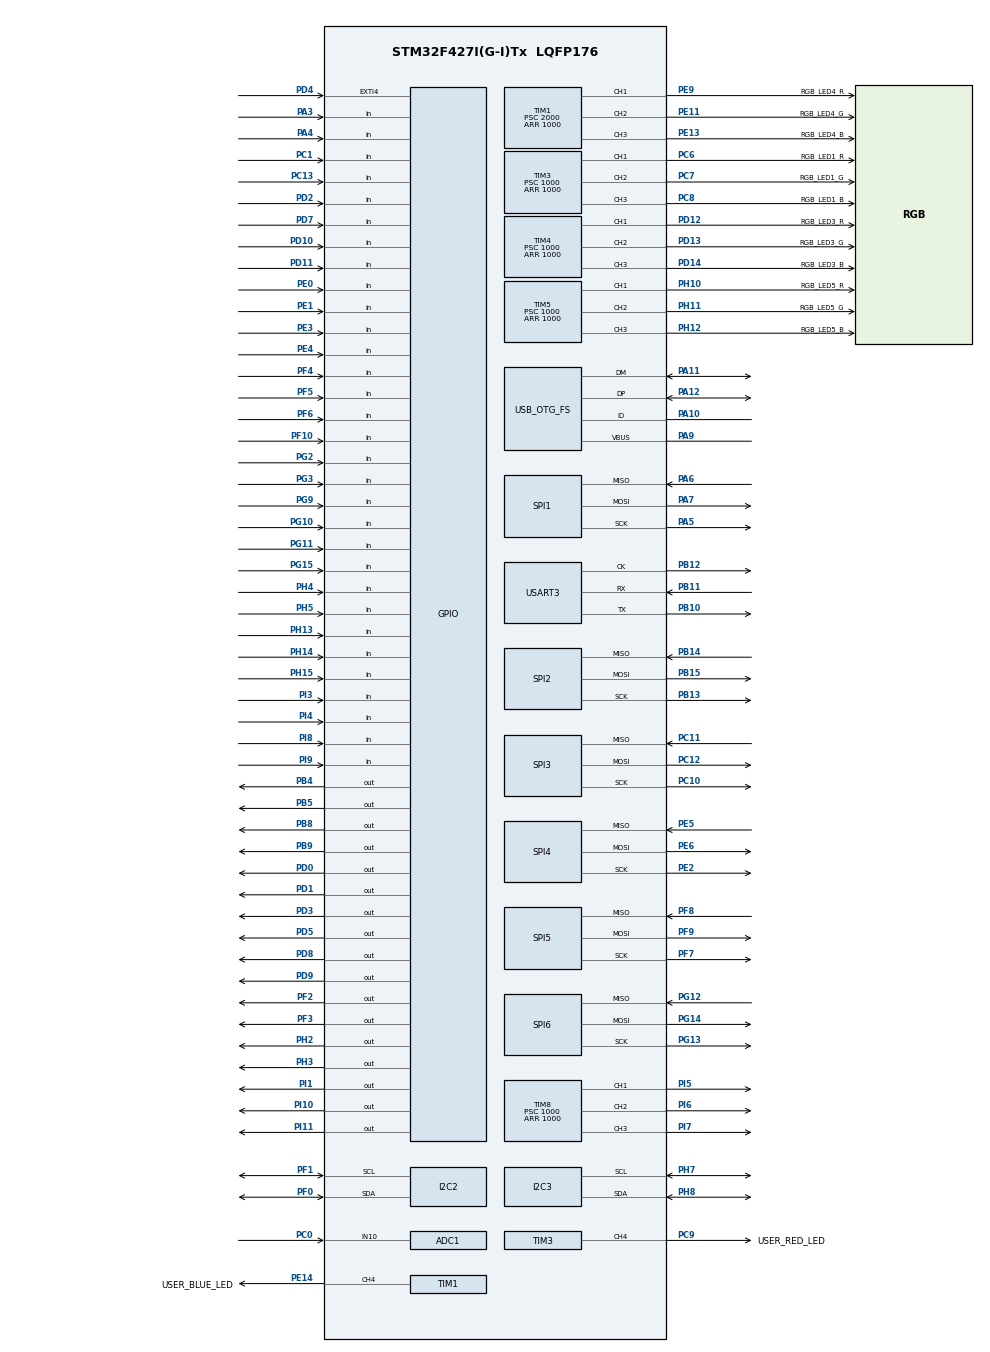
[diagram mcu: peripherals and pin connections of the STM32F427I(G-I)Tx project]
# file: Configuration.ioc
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ADC1.Channel-0\#ChannelRegularConversion=ADC_CHANNEL_10
ADC1.NbrOfConversionFlag=1
ADC1.master=1
Dma.Request0=SPI3_RX
Dma.Request1=SPI3_TX
Dma.Request10=USART3_RX
Dma.Request11=USART3_TX
Dma.Request2=SPI4_RX
Dma.Request3=SPI4_TX
Dma.Request4=SPI5_TX
Dma.Request5=SPI5_RX
Dma.Request6=SPI6_RX
Dma.Request7=SPI6_TX
Dma.Request8=SPI1_RX
Dma.Request9=SPI2_RX
Dma.SPI1_RX.8.Channel=DMA_CHANNEL_3
Dma.SPI1_RX.8.Direction=DMA_PERIPH_TO_MEMORY
Dma.SPI1_RX.8.FIFOMode=DMA_FIFOMODE_DISABLE
Dma.SPI1_RX.8.Instance=DMA2_Stream2
Dma.SPI1_RX.8.MemDataAlignment=DMA_MDATAALIGN_BYTE
Dma.SPI1_RX.8.MemInc=DMA_MINC_ENABLE
Dma.SPI1_RX.8.Mode=DMA_NORMAL
Dma.SPI1_RX.8.PeriphDataAlignment=DMA_PDATAALIGN_BYTE
Dma.SPI1_RX.8.PeriphInc=DMA_PINC_DISABLE
Dma.SPI1_RX.8.Priority=DMA_PRIORITY_HIGH
Dma.SPI2_RX.9.Channel=DMA_CHANNEL_0
Dma.SPI2_RX.9.Direction=DMA_PERIPH_TO_MEMORY
Dma.SPI2_RX.9.FIFOMode=DMA_FIFOMODE_DISABLE
Dma.SPI2_RX.9.Instance=DMA1_Stream3
Dma.SPI2_RX.9.MemDataAlignment=DMA_MDATAALIGN_BYTE
Dma.SPI2_RX.9.MemInc=DMA_MINC_ENABLE
Dma.SPI2_RX.9.Mode=DMA_NORMAL
Dma.SPI2_RX.9.PeriphDataAlignment=DMA_PDATAALIGN_BYTE
Dma.SPI2_RX.9.PeriphInc=DMA_PINC_DISABLE
Dma.SPI2_RX.9.Priority=DMA_PRIORITY_MEDIUM
Dma.SPI3_RX.0.Channel=DMA_CHANNEL_0
Dma.SPI3_RX.0.Direction=DMA_PERIPH_TO_MEMORY
Dma.SPI3_RX.0.FIFOMode=DMA_FIFOMODE_DISABLE
Dma.SPI3_RX.0.Instance=DMA1_Stream0
Dma.SPI3_RX.0.MemDataAlignment=DMA_MDATAALIGN_BYTE
Dma.SPI3_RX.0.MemInc=DMA_MINC_ENABLE
Dma.SPI3_RX.0.Mode=DMA_NORMAL
Dma.SPI3_RX.0.PeriphDataAlignment=DMA_PDATAALIGN_BYTE
Dma.SPI3_RX.0.PeriphInc=DMA_PINC_DISABLE
Dma.SPI3_RX.0.Priority=DMA_PRIORITY_MEDIUM
Dma.SPI3_TX.1.Channel=DMA_CHANNEL_0
Dma.SPI3_TX.1.Direction=DMA_MEMORY_TO_PERIPH
Dma.SPI3_TX.1.FIFOMode=DMA_FIFOMODE_DISABLE
Dma.SPI3_TX.1.Instance=DMA1_Stream7
Dma.SPI3_TX.1.MemDataAlignment=DMA_MDATAALIGN_BYTE
Dma.SPI3_TX.1.MemInc=DMA_MINC_ENABLE
Dma.SPI3_TX.1.Mode=DMA_NORMAL
Dma.SPI3_TX.1.PeriphDataAlignment=DMA_PDATAALIGN_BYTE
Dma.SPI3_TX.1.PeriphInc=DMA_PINC_DISABLE
Dma.SPI3_TX.1.Priority=DMA_PRIORITY_HIGH
Dma.SPI4_RX.2.Channel=DMA_CHANNEL_4
Dma.SPI4_RX.2.Direction=DMA_PERIPH_TO_MEMORY
Dma.SPI4_RX.2.FIFOMode=DMA_FIFOMODE_DISABLE
Dma.SPI4_RX.2.Instance=DMA2_Stream0
Dma.SPI4_RX.2.MemDataAlignment=DMA_MDATAALIGN_BYTE
Dma.SPI4_RX.2.MemInc=DMA_MINC_ENABLE
Dma.SPI4_RX.2.Mode=DMA_NORMAL
Dma.SPI4_RX.2.PeriphDataAlignment=DMA_PDATAALIGN_BYTE
Dma.SPI4_RX.2.PeriphInc=DMA_PINC_DISABLE
Dma.SPI4_RX.2.Priority=DMA_PRIORITY_MEDIUM
Dma.SPI4_TX.3.Channel=DMA_CHANNEL_4
Dma.SPI4_TX.3.Direction=DMA_MEMORY_TO_PERIPH
Dma.SPI4_TX.3.FIFOMode=DMA_FIFOMODE_DISABLE
Dma.SPI4_TX.3.Instance=DMA2_Stream1
Dma.SPI4_TX.3.MemDataAlignment=DMA_MDATAALIGN_BYTE
Dma.SPI4_TX.3.MemInc=DMA_MINC_ENABLE
Dma.SPI4_TX.3.Mode=DMA_NORMAL
Dma.SPI4_TX.3.PeriphDataAlignment=DMA_PDATAALIGN_BYTE
Dma.SPI4_TX.3.PeriphInc=DMA_PINC_DISABLE
Dma.SPI4_TX.3.Priority=DMA_PRIORITY_HIGH
Dma.SPI5_RX.5.Channel=DMA_CHANNEL_2
Dma.SPI5_RX.5.Direction=DMA_PERIPH_TO_MEMORY
Dma.SPI5_RX.5.FIFOMode=DMA_FIFOMODE_DISABLE
Dma.SPI5_RX.5.Instance=DMA2_Stream3
Dma.SPI5_RX.5.MemDataAlignment=DMA_MDATAALIGN_BYTE
Dma.SPI5_RX.5.MemInc=DMA_MINC_ENABLE
Dma.SPI5_RX.5.Mode=DMA_NORMAL
Dma.SPI5_RX.5.PeriphDataAlignment=DMA_PDATAALIGN_BYTE
Dma.SPI5_RX.5.PeriphInc=DMA_PINC_DISABLE
Dma.SPI5_RX.5.Priority=DMA_PRIORITY_HIGH
Dma.SPI5_TX.4.Channel=DMA_CHANNEL_2
Dma.SPI5_TX.4.Direction=DMA_MEMORY_TO_PERIPH
Dma.SPI5_TX.4.FIFOMode=DMA_FIFOMODE_DISABLE
Dma.SPI5_TX.4.Instance=DMA2_Stream4
Dma.SPI5_TX.4.MemDataAlignment=DMA_MDATAALIGN_BYTE
Dma.SPI5_TX.4.MemInc=DMA_MINC_ENABLE
Dma.SPI5_TX.4.Mode=DMA_NORMAL
Dma.SPI5_TX.4.PeriphDataAlignment=DMA_PDATAALIGN_BYTE
Dma.SPI5_TX.4.PeriphInc=DMA_PINC_DISABLE
Dma.SPI5_TX.4.Priority=DMA_PRIORITY_MEDIUM
Dma.SPI6_RX.6.Channel=DMA_CHANNEL_1
Dma.SPI6_RX.6.Direction=DMA_PERIPH_TO_MEMORY
Dma.SPI6_RX.6.FIFOMode=DMA_FIFOMODE_DISABLE
Dma.SPI6_RX.6.Instance=DMA2_Stream6
Dma.SPI6_RX.6.MemDataAlignment=DMA_MDATAALIGN_BYTE
Dma.SPI6_RX.6.MemInc=DMA_MINC_ENABLE
Dma.SPI6_RX.6.Mode=DMA_NORMAL
Dma.SPI6_RX.6.PeriphDataAlignment=DMA_PDATAALIGN_BYTE
Dma.SPI6_RX.6.PeriphInc=DMA_PINC_DISABLE
Dma.SPI6_RX.6.Priority=DMA_PRIORITY_HIGH
Dma.SPI6_TX.7.Channel=DMA_CHANNEL_1
Dma.SPI6_TX.7.Direction=DMA_MEMORY_TO_PERIPH
Dma.SPI6_TX.7.FIFOMode=DMA_FIFOMODE_DISABLE
Dma.SPI6_TX.7.Instance=DMA2_Stream5
Dma.SPI6_TX.7.MemDataAlignment=DMA_MDATAALIGN_BYTE
Dma.SPI6_TX.7.MemInc=DMA_MINC_ENABLE
Dma.SPI6_TX.7.Mode=DMA_NORMAL
Dma.SPI6_TX.7.PeriphDataAlignment=DMA_PDATAALIGN_BYTE
Dma.SPI6_TX.7.PeriphInc=DMA_PINC_DISABLE
Dma.SPI6_TX.7.Priority=DMA_PRIORITY_MEDIUM
Dma.USART3_RX.10.Channel=DMA_CHANNEL_4
Dma.USART3_RX.10.Direction=DMA_PERIPH_TO_MEMORY
Dma.USART3_RX.10.FIFOMode=DMA_FIFOMODE_DISABLE
Dma.USART3_RX.10.Instance=DMA1_Stream1
Dma.USART3_RX.10.MemDataAlignment=DMA_MDATAALIGN_BYTE
Dma.USART3_RX.10.MemInc=DMA_MINC_ENABLE
Dma.USART3_RX.10.Mode=DMA_NORMAL
Dma.USART3_RX.10.PeriphDataAlignment=DMA_PDATAALIGN_BYTE
Dma.USART3_RX.10.PeriphInc=DMA_PINC_DISABLE
Dma.USART3_RX.10.Priority=DMA_PRIORITY_MEDIUM
Dma.USART3_TX.11.Channel=DMA_CHANNEL_7
Dma.USART3_TX.11.Direction=DMA_MEMORY_TO_PERIPH
Dma.USART3_TX.11.FIFOMode=DMA_FIFOMODE_DISABLE
Dma.USART3_TX.11.Instance=DMA1_Stream4
Dma.USART3_TX.11.MemDataAlignment=DMA_MDATAALIGN_BYTE
Dma.USART3_TX.11.MemInc=DMA_MINC_ENABLE
Dma.USART3_TX.11.Mode=DMA_NORMAL
Dma.USART3_TX.11.PeriphDataAlignment=DMA_PDATAALIGN_BYTE
Dma.USART3_TX.11.PeriphInc=DMA_PINC_DISABLE
Dma.USART3_TX.11.Priority=DMA_PRIORITY_VERY_HIGH
Mcu.Family=STM32F4
Mcu.Name=STM32F427I(G-I)Tx
Mcu.Package=LQFP176
NVIC.DMA1_Stream0_IRQn=true\:8\:0
NVIC.DMA1_Stream1_IRQn=true\:2\:0
NVIC.DMA1_Stream3_IRQn=true\:8\:0
NVIC.DMA1_Stream4_IRQn=true\:2\:0
NVIC.DMA1_Stream7_IRQn=true\:7\:0
NVIC.DMA2_Stream0_IRQn=true\:8\:0
NVIC.DMA2_Stream1_IRQn=true\:7\:0
NVIC.DMA2_Stream2_IRQn=true\:8\:0
NVIC.DMA2_Stream3_IRQn=true\:8\:0
NVIC.DMA2_Stream4_IRQn=true\:7\:0
NVIC.DMA2_Stream5_IRQn=true\:7\:0
NVIC.DMA2_Stream6_IRQn=true\:8\:0
NVIC.EXTI4_IRQn=true\:3\:0
NVIC.PriorityGroup=NVIC_PRIORITYGROUP_4
NVIC.SPI1_IRQn=true\:5\:0
NVIC.SPI2_IRQn=true\:5\:0
PA0/WKUP.Mode=SYS-WakeUp
PA0/WKUP.Signal=SYS_WKUP
PA10.Mode=OTG/Dual_Role_Device
PA10.Signal=USB_OTG_FS_ID
PA11.Mode=OTG/Dual_Role_Device
PA11.Signal=USB_OTG_FS_DM
PA12.Mode=OTG/Dual_Role_Device
PA12.Signal=USB_OTG_FS_DP
PA13.Mode=JTAG(4-pin)
PA13.Signal=SYS_JTMS-SWDIO
PA14.Mode=JTAG(4-pin)
PA14.Signal=SYS_JTCK-SWCLK
PA15.Mode=JTAG(4-pin)
PA15.Signal=SYS_JTDI
PA3.GPIO_Mode=GPIO_MODE_INPUT
PA3.GPIO_PuPd=GPIO_PULLDOWN
PA3.Signal=GPIO_Input
PA4.GPIO_Mode=GPIO_MODE_INPUT
PA4.GPIO_PuPd=GPIO_PULLDOWN
PA4.Signal=GPIO_Input
PA5.GPIO_Mode=GPIO_MODE_AF_PP
PA5.GPIO_PuPd=GPIO_NOPULL
PA5.GPIO_Speed=GPIO_SPEED_MEDIUM
PA5.Mode=Full_Duplex_Master
PA5.Signal=SPI1_SCK
PA6.GPIO_Mode=GPIO_MODE_AF_PP
PA6.GPIO_PuPd=GPIO_NOPULL
PA6.GPIO_Speed=GPIO_SPEED_MEDIUM
PA6.Mode=Full_Duplex_Master
PA6.Signal=SPI1_MISO
PA7.GPIO_Mode=GPIO_MODE_AF_PP
PA7.GPIO_PuPd=GPIO_NOPULL
PA7.GPIO_Speed=GPIO_SPEED_MEDIUM
PA7.Mode=Full_Duplex_Master
PA7.Signal=SPI1_MOSI
PA9.Mode=Activate_VBUS
PA9.Signal=USB_OTG_FS_VBUS
PB10.Mode=Synchronous
PB10.Signal=USART3_TX
PB11.Mode=Synchronous
PB11.Signal=USART3_RX
PB12.Mode=Synchronous
PB12.Signal=USART3_CK
PB13.GPIO_Mode=GPIO_MODE_AF_PP
PB13.GPIO_PuPd=GPIO_NOPULL
PB13.GPIO_Speed=GPIO_SPEED_MEDIUM
PB13.Mode=Full_Duplex_Master
PB13.Signal=SPI2_SCK
PB14.GPIO_Mode=GPIO_MODE_AF_PP
PB14.GPIO_PuPd=GPIO_NOPULL
PB14.GPIO_Speed=GPIO_SPEED_MEDIUM
PB14.Mode=Full_Duplex_Master
PB14.Signal=SPI2_MISO
PB15.GPIO_Mode=GPIO_MODE_AF_PP
PB15.GPIO_PuPd=GPIO_NOPULL
PB15.GPIO_Speed=GPIO_SPEED_MEDIUM
PB15.Mode=Full_Duplex_Master
PB15.Signal=SPI2_MOSI
PB3.Mode=JTAG(4-pin)
PB3.Signal=SYS_JTDO-SWO
PB4.GPIO_ModeDefaultOutputPP=GPIO_MODE_OUTPUT_OD
PB4.GPIO_PuPd=GPIO_PULLUP
PB4.GPIO_Speed=GPIO_SPEED_LOW
PB4.Signal=GPIO_Output
PB5.GPIO_ModeDefaultOutputPP=GPIO_MODE_OUTPUT_OD
PB5.GPIO_PuPd=GPIO_PULLUP
PB5.GPIO_Speed=GPIO_SPEED_LOW
PB5.Signal=GPIO_Output
PB8.GPIO_ModeDefaultOutputPP=GPIO_MODE_OUTPUT_OD
PB8.GPIO_PuPd=GPIO_PULLUP
PB8.GPIO_Speed=GPIO_SPEED_LOW
PB8.Signal=GPIO_Output
PB9.GPIO_ModeDefaultOutputPP=GPIO_MODE_OUTPUT_OD
PB9.GPIO_PuPd=GPIO_PULLUP
PB9.GPIO_Speed=GPIO_SPEED_LOW
PB9.Signal=GPIO_Output
PC0.Signal=ADCx_IN10
PC1.Signal=GPIO_Input
PC10.GPIO_Mode=GPIO_MODE_AF_PP
PC10.GPIO_PuPd=GPIO_NOPULL
PC10.GPIO_Speed=GPIO_SPEED_MEDIUM
PC10.Mode=Full_Duplex_Master
PC10.Signal=SPI3_SCK
PC11.GPIO_Mode=GPIO_MODE_AF_PP
PC11.GPIO_PuPd=GPIO_NOPULL
PC11.GPIO_Speed=GPIO_SPEED_MEDIUM
PC11.Mode=Full_Duplex_Master
PC11.Signal=SPI3_MISO
PC12.GPIO_Mode=GPIO_MODE_AF_PP
PC12.GPIO_PuPd=GPIO_NOPULL
PC12.GPIO_Speed=GPIO_SPEED_MEDIUM
PC12.Mode=Full_Duplex_Master
PC12.Signal=SPI3_MOSI
PC13.GPIO_Mode=GPIO_MODE_INPUT
PC13.GPIO_PuPd=GPIO_PULLDOWN
PC13.Signal=GPIO_Input
PC6.GPIO_Label=RGB_LED1_R
PC6.GPIO_ModeDefaultPP=GPIO_MODE_AF_OD
PC6.GPIO_PuPd=GPIO_PULLUP
PC6.GPIO_Speed=GPIO_SPEED_LOW
PC6.Signal=S_TIM3_CH1
PC7.GPIO_Label=RGB_LED1_G
PC7.GPIO_ModeDefaultPP=GPIO_MODE_AF_OD
PC7.GPIO_PuPd=GPIO_PULLUP
PC7.GPIO_Speed=GPIO_SPEED_LOW
PC7.Signal=S_TIM3_CH2
PC8.GPIO_Label=RGB_LED1_B
PC8.GPIO_ModeDefaultPP=GPIO_MODE_AF_OD
PC8.GPIO_PuPd=GPIO_PULLUP
PC8.GPIO_Speed=GPIO_SPEED_LOW
PC8.Signal=S_TIM3_CH3
PC9.GPIO_Label=USER_RED_LED
PC9.GPIO_ModeDefaultPP=GPIO_MODE_AF_OD
PC9.GPIO_PuPd=GPIO_PULLUP
PC9.GPIO_Speed=GPIO_SPEED_LOW
PC9.Signal=S_TIM3_CH4
PD0.GPIO_ModeDefaultOutputPP=GPIO_MODE_OUTPUT_OD
PD0.GPIO_PuPd=GPIO_PULLUP
PD0.GPIO_Speed=GPIO_SPEED_LOW
PD0.Signal=GPIO_Output
PD1.GPIO_ModeDefaultOutputPP=GPIO_MODE_OUTPUT_OD
PD1.GPIO_PuPd=GPIO_PULLUP
PD1.GPIO_Speed=GPIO_SPEED_LOW
PD1.Signal=GPIO_Output
PD10.GPIO_Mode=GPIO_MODE_INPUT
PD10.GPIO_PuPd=GPIO_PULLDOWN
PD10.Signal=GPIO_Input
PD11.GPIO_Mode=GPIO_MODE_INPUT
PD11.GPIO_PuPd=GPIO_PULLDOWN
PD11.Signal=GPIO_Input
PD12.GPIO_Label=RGB_LED3_R
PD12.GPIO_ModeDefaultPP=GPIO_MODE_AF_OD
PD12.GPIO_PuPd=GPIO_PULLUP
PD12.GPIO_Speed=GPIO_SPEED_LOW
PD12.Signal=S_TIM4_CH1
PD13.GPIO_Label=RGB_LED3_G
PD13.GPIO_ModeDefaultPP=GPIO_MODE_AF_OD
PD13.GPIO_PuPd=GPIO_PULLUP
PD13.GPIO_Speed=GPIO_SPEED_LOW
PD13.Signal=S_TIM4_CH2
PD14.GPIO_Label=RGB_LED3_B
PD14.GPIO_ModeDefaultPP=GPIO_MODE_AF_OD
PD14.GPIO_PuPd=GPIO_PULLUP
PD14.GPIO_Speed=GPIO_SPEED_LOW
PD14.Signal=S_TIM4_CH3
PD2.GPIO_Mode=GPIO_MODE_INPUT
PD2.GPIO_PuPd=GPIO_PULLDOWN
PD2.Signal=GPIO_Input
PD3.Signal=GPIO_Output
PD4.GPIO_ModeDefaultEXTI=GPIO_MODE_IT_FALLING
PD4.GPIO_PuPd=GPIO_NOPULL
PD4.Signal=GPXTI4
PD5.Signal=GPIO_Output
PD7.GPIO_Mode=GPIO_MODE_INPUT
PD7.GPIO_PuPd=GPIO_PULLDOWN
PD7.Signal=GPIO_Input
PD8.GPIO_ModeDefaultOutputPP=GPIO_MODE_OUTPUT_OD
PD8.GPIO_PuPd=GPIO_PULLUP
PD8.GPIO_Speed=GPIO_SPEED_LOW
PD8.Signal=GPIO_Output
PD9.GPIO_ModeDefaultOutputPP=GPIO_MODE_OUTPUT_OD
PD9.GPIO_PuPd=GPIO_PULLUP
PD9.GPIO_Speed=GPIO_SPEED_LOW
PD9.Signal=GPIO_Output
PE0.GPIO_Mode=GPIO_MODE_INPUT
PE0.GPIO_PuPd=GPIO_PULLDOWN
PE0.Signal=GPIO_Input
PE1.GPIO_Mode=GPIO_MODE_INPUT
PE1.GPIO_PuPd=GPIO_PULLDOWN
PE1.Signal=GPIO_Input
PE11.GPIO_Label=RGB_LED4_G
PE11.GPIO_ModeDefaultPP=GPIO_MODE_AF_OD
PE11.GPIO_PuPd=GPIO_PULLUP
PE11.GPIO_Speed=GPIO_SPEED_LOW
PE11.Signal=S_TIM1_CH2
PE13.GPIO_Label=RGB_LED4_B
PE13.GPIO_ModeDefaultPP=GPIO_MODE_AF_OD
PE13.GPIO_PuPd=GPIO_PULLUP
PE13.GPIO_Speed=GPIO_SPEED_LOW
PE13.Signal=S_TIM1_CH3
PE14.GPIO_Label=USER_BLUE_LED
PE14.GPIO_ModeDefaultPP=GPIO_MODE_AF_OD
PE14.GPIO_PuPd=GPIO_PULLUP
PE14.GPIO_Speed=GPIO_SPEED_LOW
PE14.Signal=S_TIM1_CH4
PE2.GPIO_Mode=GPIO_MODE_AF_PP
PE2.GPIO_PuPd=GPIO_NOPULL
PE2.GPIO_Speed=GPIO_SPEED_MEDIUM
PE2.Mode=Full_Duplex_Master
PE2.Signal=SPI4_SCK
PE3.GPIO_Mode=GPIO_MODE_INPUT
PE3.GPIO_PuPd=GPIO_PULLDOWN
PE3.Signal=GPIO_Input
PE4.GPIO_Mode=GPIO_MODE_INPUT
PE4.GPIO_PuPd=GPIO_PULLDOWN
PE4.Signal=GPIO_Input
PE5.GPIO_Mode=GPIO_MODE_AF_PP
PE5.GPIO_PuPd=GPIO_NOPULL
PE5.GPIO_Speed=GPIO_SPEED_MEDIUM
PE5.Mode=Full_Duplex_Master
PE5.Signal=SPI4_MISO
PE6.GPIO_Mode=GPIO_MODE_AF_PP
PE6.GPIO_PuPd=GPIO_NOPULL
PE6.GPIO_Speed=GPIO_SPEED_MEDIUM
PE6.Mode=Full_Duplex_Master
PE6.Signal=SPI4_MOSI
PE9.GPIO_Label=RGB_LED4_R
PE9.GPIO_ModeDefaultPP=GPIO_MODE_AF_OD
PE9.GPIO_PuPd=GPIO_PULLUP
PE9.GPIO_Speed=GPIO_SPEED_LOW
PE9.Signal=S_TIM1_CH1
PF0.Mode=I2C
PF0.Signal=I2C2_SDA
PF1.Mode=I2C
PF1.Signal=I2C2_SCL
PF10.GPIO_Mode=GPIO_MODE_INPUT
PF10.GPIO_PuPd=GPIO_PULLDOWN
PF10.Signal=GPIO_Input
PF2.GPIO_ModeDefaultOutputPP=GPIO_MODE_OUTPUT_OD
PF2.GPIO_PuPd=GPIO_PULLUP
PF2.GPIO_Speed=GPIO_SPEED_LOW
PF2.Signal=GPIO_Output
PF3.GPIO_ModeDefaultOutputPP=GPIO_MODE_OUTPUT_OD
PF3.GPIO_PuPd=GPIO_PULLUP
PF3.GPIO_Speed=GPIO_SPEED_LOW
PF3.Signal=GPIO_Output
PF4.GPIO_Mode=GPIO_MODE_INPUT
PF4.GPIO_PuPd=GPIO_PULLDOWN
PF4.Signal=GPIO_Input
PF5.GPIO_Mode=GPIO_MODE_INPUT
PF5.GPIO_PuPd=GPIO_PULLDOWN
PF5.Signal=GPIO_Input
PF6.GPIO_Mode=GPIO_MODE_INPUT
PF6.GPIO_PuPd=GPIO_PULLDOWN
PF6.Signal=GPIO_Input
PF7.GPIO_Mode=GPIO_MODE_AF_PP
PF7.GPIO_PuPd=GPIO_NOPULL
PF7.GPIO_Speed=GPIO_SPEED_MEDIUM
PF7.Mode=Full_Duplex_Master
PF7.Signal=SPI5_SCK
PF8.GPIO_Mode=GPIO_MODE_AF_PP
PF8.GPIO_PuPd=GPIO_NOPULL
PF8.GPIO_Speed=GPIO_SPEED_MEDIUM
PF8.Mode=Full_Duplex_Master
PF8.Signal=SPI5_MISO
PF9.GPIO_Mode=GPIO_MODE_AF_PP
PF9.GPIO_PuPd=GPIO_NOPULL
PF9.GPIO_Speed=GPIO_SPEED_MEDIUM
PF9.Mode=Full_Duplex_Master
PF9.Signal=SPI5_MOSI
PG10.GPIO_Mode=GPIO_MODE_INPUT
PG10.GPIO_PuPd=GPIO_PULLDOWN
PG10.Signal=GPIO_Input
PG11.GPIO_Mode=GPIO_MODE_INPUT
PG11.GPIO_PuPd=GPIO_PULLDOWN
PG11.Signal=GPIO_Input
PG12.GPIO_Mode=GPIO_MODE_AF_PP
PG12.GPIO_PuPd=GPIO_NOPULL
PG12.GPIO_Speed=GPIO_SPEED_MEDIUM
PG12.Mode=Full_Duplex_Master
PG12.Signal=SPI6_MISO
PG13.GPIO_Mode=GPIO_MODE_AF_PP
PG13.GPIO_PuPd=GPIO_NOPULL
PG13.GPIO_Speed=GPIO_SPEED_MEDIUM
PG13.Mode=Full_Duplex_Master
PG13.Signal=SPI6_SCK
PG14.GPIO_Mode=GPIO_MODE_AF_PP
PG14.GPIO_PuPd=GPIO_NOPULL
PG14.GPIO_Speed=GPIO_SPEED_MEDIUM
PG14.Mode=Full_Duplex_Master
PG14.Signal=SPI6_MOSI
PG15.GPIO_Mode=GPIO_MODE_INPUT
PG15.GPIO_PuPd=GPIO_PULLUP
PG15.Signal=GPIO_Input
PG2.GPIO_Mode=GPIO_MODE_INPUT
PG2.GPIO_PuPd=GPIO_PULLDOWN
PG2.Signal=GPIO_Input
PG3.GPIO_Mode=GPIO_MODE_INPUT
PG3.GPIO_PuPd=GPIO_PULLDOWN
PG3.Signal=GPIO_Input
PG9.GPIO_Mode=GPIO_MODE_INPUT
PG9.GPIO_PuPd=GPIO_PULLDOWN
PG9.Signal=GPIO_Input
PH0/OSC_IN.Mode=HSE-External-Oscillator
PH0/OSC_IN.Signal=RCC_OSC_IN
PH1/OSC_OUT.Mode=HSE-External-Oscillator
PH1/OSC_OUT.Signal=RCC_OSC_OUT
PH10.GPIO_Label=RGB_LED5_R
PH10.GPIO_ModeDefaultPP=GPIO_MODE_AF_OD
PH10.GPIO_PuPd=GPIO_PULLUP
PH10.GPIO_Speed=GPIO_SPEED_LOW
PH10.Signal=S_TIM5_CH1
PH11.GPIO_Label=RGB_LED5_G
PH11.GPIO_ModeDefaultPP=GPIO_MODE_AF_OD
PH11.GPIO_PuPd=GPIO_PULLUP
PH11.GPIO_Speed=GPIO_SPEED_LOW
PH11.Signal=S_TIM5_CH2
PH12.GPIO_Label=RGB_LED5_B
PH12.GPIO_ModeDefaultPP=GPIO_MODE_AF_OD
PH12.GPIO_PuPd=GPIO_PULLUP
PH12.GPIO_Speed=GPIO_SPEED_LOW
PH12.Signal=S_TIM5_CH3
PH13.GPIO_Mode=GPIO_MODE_INPUT
PH13.GPIO_PuPd=GPIO_PULLDOWN
PH13.Signal=GPIO_Input
PH14.GPIO_Mode=GPIO_MODE_INPUT
PH14.GPIO_PuPd=GPIO_PULLDOWN
PH14.Signal=GPIO_Input
PH15.GPIO_Mode=GPIO_MODE_INPUT
PH15.GPIO_PuPd=GPIO_PULLDOWN
PH15.Signal=GPIO_Input
PH2.GPIO_ModeDefaultOutputPP=GPIO_MODE_OUTPUT_OD
PH2.GPIO_PuPd=GPIO_PULLUP
PH2.GPIO_Speed=GPIO_SPEED_LOW
PH2.Signal=GPIO_Output
PH3.GPIO_ModeDefaultOutputPP=GPIO_MODE_OUTPUT_OD
PH3.GPIO_PuPd=GPIO_PULLUP
PH3.GPIO_Speed=GPIO_SPEED_LOW
PH3.Signal=GPIO_Output
PH4.GPIO_Mode=GPIO_MODE_INPUT
PH4.GPIO_PuPd=GPIO_PULLDOWN
PH4.Signal=GPIO_Input
PH5.GPIO_Mode=GPIO_MODE_INPUT
PH5.GPIO_PuPd=GPIO_PULLDOWN
PH5.Signal=GPIO_Input
PH7.Mode=I2C
PH7.Signal=I2C3_SCL
PH8.Mode=I2C
PH8.Signal=I2C3_SDA
PI1.Signal=GPIO_Output
PI10.GPIO_ModeDefaultOutputPP=GPIO_MODE_OUTPUT_OD
PI10.GPIO_PuPd=GPIO_PULLUP
PI10.GPIO_Speed=GPIO_SPEED_LOW
PI10.Signal=GPIO_Output
PI11.GPIO_ModeDefaultOutputPP=GPIO_MODE_OUTPUT_OD
PI11.GPIO_PuPd=GPIO_PULLUP
PI11.GPIO_Speed=GPIO_SPEED_LOW
PI11.Signal=GPIO_Output
PI3.Signal=GPIO_Input
PI4.GPIO_Mode=GPIO_MODE_INPUT
PI4.GPIO_PuPd=GPIO_PULLDOWN
PI4.Signal=GPIO_Input
PI5.GPIO_ModeDefaultPP=GPIO_MODE_AF_OD
PI5.GPIO_PuPd=GPIO_PULLUP
PI5.GPIO_Speed=GPIO_SPEED_LOW
PI5.Signal=S_TIM8_CH1
PI6.GPIO_ModeDefaultPP=GPIO_MODE_AF_OD
PI6.GPIO_PuPd=GPIO_PULLUP
PI6.GPIO_Speed=GPIO_SPEED_LOW
PI6.Signal=S_TIM8_CH2
PI7.GPIO_ModeDefaultPP=GPIO_MODE_AF_OD
PI7.GPIO_PuPd=GPIO_PULLUP
PI7.GPIO_Speed=GPIO_SPEED_LOW
PI7.Signal=S_TIM8_CH3
PI8.GPIO_Mode=GPIO_MODE_INPUT
PI8.GPIO_PuPd=GPIO_PULLDOWN
PI8.Signal=GPIO_Input
PI9.GPIO_Mode=GPIO_MODE_INPUT
PI9.GPIO_PuPd=GPIO_PULLDOWN
PI9.Signal=GPIO_Input
ProjectManager.TargetToolchain=TrueSTUDIO 4.3.1
RCC.APB1CLKDivider=RCC_HCLK_DIV4
RCC.APB2CLKDivider=RCC_HCLK_DIV2
RCC.HSE_VALUE=25000000
RCC.HSI_VALUE=16000000
RCC.LSE_VALUE=32768
RCC.PLLN=336
RCC.PLLQ=7
RCC.RCC_MCO1Source=RCC_MCO1SOURCE_HSE
RCC.RCC_MCODiv1=RCC_MCODIV_5
RCC.SYSCLKSource=RCC_SYSCLKSOURCE_PLLCLK
SH.ADCx_IN10.0=ADC1_IN10,IN10
SH.S_TIM1_CH1.0=TIM1_CH1,PWM Generation1 CH1
SH.S_TIM1_CH2.0=TIM1_CH2,PWM Generation2 CH2
SH.S_TIM1_CH3.0=TIM1_CH3,PWM Generation3 CH3
SH.S_TIM1_CH4.0=TIM1_CH4,PWM Generation4 CH4
SH.S_TIM3_CH1.0=TIM3_CH1,PWM Generation1 CH1
SH.S_TIM3_CH2.0=TIM3_CH2,PWM Generation2 CH2
SH.S_TIM3_CH3.0=TIM3_CH3,PWM Generation3 CH3
SH.S_TIM3_CH4.0=TIM3_CH4,PWM Generation4 CH4
SH.S_TIM4_CH1.0=TIM4_CH1,PWM Generation1 CH1
SH.S_TIM4_CH2.0=TIM4_CH2,PWM Generation2 CH2
SH.S_TIM4_CH3.0=TIM4_CH3,PWM Generation3 CH3
SH.S_TIM5_CH1.0=TIM5_CH1,PWM Generation1 CH1
SH.S_TIM5_CH2.0=TIM5_CH2,PWM Generation2 CH2
SH.S_TIM5_CH3.0=TIM5_CH3,PWM Generation3 CH3
SH.S_TIM8_CH1.0=TIM8_CH1,PWM Generation1 CH1
SH.S_TIM8_CH2.0=TIM8_CH2,PWM Generation2 CH2
SH.S_TIM8_CH3.0=TIM8_CH3,PWM Generation3 CH3
SPI1.BaudRatePrescaler-Full_Duplex_Master=SPI_BAUDRATEPRESCALER_32
SPI1.CLKPhase-Full_Duplex_Master=SPI_PHASE_2EDGE
SPI1.CLKPolarity-Full_Duplex_Master=SPI_POLARITY_HIGH
SPI1.CalculateBaudRate-Full_Duplex_Master=2.625 MBits/s
SPI1.Mode-Full_Duplex_Master=SPI_MODE_MASTER
SPI2.BaudRatePrescaler-Full_Duplex_Master=SPI_BAUDRATEPRESCALER_16
SPI2.CLKPhase-Full_Duplex_Master=SPI_PHASE_2EDGE
SPI2.CLKPolarity-Full_Duplex_Master=SPI_POLARITY_HIGH
SPI2.CalculateBaudRate-Full_Duplex_Master=2.625 MBits/s
SPI2.Mode-Full_Duplex_Master=SPI_MODE_MASTER
SPI3.BaudRatePrescaler-Full_Duplex_Master=SPI_BAUDRATEPRESCALER_16
SPI3.CLKPhase-Full_Duplex_Master=SPI_PHASE_2EDGE
SPI3.CLKPolarity-Full_Duplex_Master=SPI_POLARITY_HIGH
SPI3.CalculateBaudRate-Full_Duplex_Master=2.625 MBits/s
SPI3.Mode-Full_Duplex_Master=SPI_MODE_MASTER
SPI4.BaudRatePrescaler-Full_Duplex_Master=SPI_BAUDRATEPRESCALER_32
SPI4.CLKPhase-Full_Duplex_Master=SPI_PHASE_2EDGE
SPI4.CLKPolarity-Full_Duplex_Master=SPI_POLARITY_HIGH
SPI4.CalculateBaudRate-Full_Duplex_Master=2.625 MBits/s
SPI4.Mode-Full_Duplex_Master=SPI_MODE_MASTER
SPI5.BaudRatePrescaler-Full_Duplex_Master=SPI_BAUDRATEPRESCALER_32
SPI5.CLKPhase-Full_Duplex_Master=SPI_PHASE_2EDGE
SPI5.CLKPolarity-Full_Duplex_Master=SPI_POLARITY_HIGH
SPI5.CalculateBaudRate-Full_Duplex_Master=2.625 MBits/s
SPI5.Mode-Full_Duplex_Master=SPI_MODE_MASTER
SPI6.BaudRatePrescaler-Full_Duplex_Master=SPI_BAUDRATEPRESCALER_32
SPI6.CLKPhase-Full_Duplex_Master=SPI_PHASE_2EDGE
SPI6.CLKPolarity-Full_Duplex_Master=SPI_POLARITY_HIGH
SPI6.CalculateBaudRate-Full_Duplex_Master=2.625 MBits/s
SPI6.Mode-Full_Duplex_Master=SPI_MODE_MASTER
TIM1.AutomaticOutput=TIM_AUTOMATICOUTPUT_DISABLE
TIM1.BreakPolarity=TIM_BREAKPOLARITY_LOW
TIM1.BreakState=TIM_BREAK_DISABLE
TIM1.Channel-PWM\ Generation2\ CH2=TIM_CHANNEL_2
TIM1.Channel-PWM\ Generation3\ CH3=TIM_CHANNEL_3
TIM1.Channel-PWM\ Generation4\ CH4=TIM_CHANNEL_4
TIM1.ClockDivision=TIM_CLOCKDIVISION_DIV4
TIM1.OCIdleState_1-PWM\ Generation1\ CH1=TIM_OCIDLESTATE_SET
TIM1.OCIdleState_2-PWM\ Generation2\ CH2=TIM_OCIDLESTATE_SET
TIM1.OCIdleState_3-PWM\ Generation3\ CH3=TIM_OCIDLESTATE_SET
TIM1.OCIdleState_4-PWM\ Generation4\ CH4=TIM_OCIDLESTATE_SET
TIM1.OCPolarity_1-PWM\ Generation1\ CH1=TIM_OCPOLARITY_LOW
TIM1.OCPolarity_2-PWM\ Generation2\ CH2=TIM_OCPOLARITY_LOW
TIM1.OCPolarity_3-PWM\ Generation3\ CH3=TIM_OCPOLARITY_LOW
TIM1.OCPolarity_4-PWM\ Generation4\ CH4=TIM_OCPOLARITY_LOW
TIM1.OffStateIDLEMode=TIM_OSSI_DISABLE
TIM1.OffStateRunMode=TIM_OSSR_DISABLE
TIM1.Period=1000
TIM1.Prescaler=2000
TIM1.Pulse-PWM\ Generation1\ CH1=250
TIM1.Pulse-PWM\ Generation2\ CH2=250
TIM1.Pulse-PWM\ Generation3\ CH3=250
TIM1.Pulse-PWM\ Generation4\ CH4=250
TIM1.TIM_MasterOutputTrigger=TIM_TRGO_RESET
TIM1.TIM_MasterSlaveMode=TIM_MASTERSLAVEMODE_DISABLE
TIM3.Channel-PWM\ Generation2\ CH2=TIM_CHANNEL_2
TIM3.Channel-PWM\ Generation3\ CH3=TIM_CHANNEL_3
TIM3.Channel-PWM\ Generation4\ CH4=TIM_CHANNEL_4
TIM3.ClockDivision=TIM_CLOCKDIVISION_DIV4
TIM3.OCPolarity_1-PWM\ Generation1\ CH1=TIM_OCPOLARITY_LOW
TIM3.OCPolarity_2-PWM\ Generation2\ CH2=TIM_OCPOLARITY_LOW
TIM3.OCPolarity_3-PWM\ Generation3\ CH3=TIM_OCPOLARITY_LOW
TIM3.OCPolarity_4-PWM\ Generation4\ CH4=TIM_OCPOLARITY_LOW
TIM3.Period=1000
TIM3.Prescaler=1000
TIM3.Pulse-PWM\ Generation1\ CH1=500
TIM3.Pulse-PWM\ Generation2\ CH2=500
TIM3.Pulse-PWM\ Generation3\ CH3=500
TIM3.Pulse-PWM\ Generation4\ CH4=500
TIM4.Channel-PWM\ Generation2\ CH2=TIM_CHANNEL_2
TIM4.Channel-PWM\ Generation3\ CH3=TIM_CHANNEL_3
TIM4.ClockDivision=TIM_CLOCKDIVISION_DIV4
TIM4.OCPolarity_1-PWM\ Generation1\ CH1=TIM_OCPOLARITY_LOW
TIM4.OCPolarity_2-PWM\ Generation2\ CH2=TIM_OCPOLARITY_LOW
TIM4.OCPolarity_3-PWM\ Generation3\ CH3=TIM_OCPOLARITY_LOW
TIM4.Period=1000
TIM4.Prescaler=1000
TIM4.Pulse-PWM\ Generation1\ CH1=500
TIM4.Pulse-PWM\ Generation2\ CH2=500
TIM4.Pulse-PWM\ Generation3\ CH3=500
TIM5.Channel-PWM\ Generation2\ CH2=TIM_CHANNEL_2
TIM5.Channel-PWM\ Generation3\ CH3=TIM_CHANNEL_3
TIM5.ClockDivision=TIM_CLOCKDIVISION_DIV4
TIM5.OCPolarity_1-PWM\ Generation1\ CH1=TIM_OCPOLARITY_LOW
TIM5.OCPolarity_2-PWM\ Generation2\ CH2=TIM_OCPOLARITY_LOW
TIM5.OCPolarity_3-PWM\ Generation3\ CH3=TIM_OCPOLARITY_LOW
TIM5.Period=1000
TIM5.Prescaler=1000
TIM5.Pulse-PWM\ Generation1\ CH1=500
TIM5.Pulse-PWM\ Generation2\ CH2=500
TIM5.Pulse-PWM\ Generation3\ CH3=500
TIM6.Prescaler=42
TIM8.Channel-PWM\ Generation2\ CH2=TIM_CHANNEL_2
TIM8.Channel-PWM\ Generation3\ CH3=TIM_CHANNEL_3
TIM8.ClockDivision=TIM_CLOCKDIVISION_DIV4
TIM8.OCIdleState_1-PWM\ Generation1\ CH1=TIM_OCIDLESTATE_SET
TIM8.OCIdleState_2-PWM\ Generation2\ CH2=TIM_OCIDLESTATE_SET
TIM8.OCIdleState_3-PWM\ Generation3\ CH3=TIM_OCIDLESTATE_SET
TIM8.OCPolarity_1-PWM\ Generation1\ CH1=TIM_OCPOLARITY_LOW
TIM8.OCPolarity_2-PWM\ Generation2\ CH2=TIM_OCPOLARITY_LOW
TIM8.OCPolarity_3-PWM\ Generation3\ CH3=TIM_OCPOLARITY_LOW
TIM8.Period=1000
TIM8.Prescaler=1000
TIM8.Pulse-PWM\ Generation1\ CH1=500
TIM8.Pulse-PWM\ Generation2\ CH2=500
TIM8.Pulse-PWM\ Generation3\ CH3=500
USART3.BaudRate-Synchronous=1750000
USART3.CLKLastBit-Synchronous=USART_LASTBIT_ENABLE
USART3.CLKPhase-Synchronous=USART_PHASE_2EDGE
USART3.VirtualMode-Synchronous=VM_SYNC
VP_TIM1_VS_ClockSourceINT.Mode=Internal
VP_TIM3_VS_ClockSourceINT.Mode=Internal
VP_TIM4_VS_ClockSourceINT.Mode=Internal
VP_TIM5_VS_ClockSourceINT.Mode=Internal
VP_TIM6_VS_ClockSourceINT.Mode=Enable_Timer
VP_TIM8_VS_ClockSourceINT.Mode=Internal

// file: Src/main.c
/**
  ******************************************************************************
  * File Name          : main.c
  * Date               : 15/11/2014 11:35:13
  * Description        : Main program body
  ******************************************************************************
  *
  * COPYRIGHT(c) 2014 STMicroelectronics
  *
  * Redistribution and use in source and binary forms, with or without modification,
  * are permitted provided that the following conditions are met:
  *   1. Redistributions of source code must retain the above copyright notice,
  *      this list of conditions and the following disclaimer.
  *   2. Redistributions in binary form must reproduce the above copyright notice,
  *      this list of conditions and the following disclaimer in the documentation
  *      and/or other materials provided with the distribution.
  *   3. Neither the name of STMicroelectronics nor the names of its contributors
  *      may be used to endorse or promote products derived from this software
  *      without specific prior written permission.
  *
  * THIS SOFTWARE IS PROVIDED BY THE COPYRIGHT HOLDERS AND CONTRIBUTORS "AS IS"
  * AND ANY EXPRESS OR IMPLIED WARRANTIES, INCLUDING, BUT NOT LIMITED TO, THE
  * IMPLIED WARRANTIES OF MERCHANTABILITY AND FITNESS FOR A PARTICULAR PURPOSE ARE
  * DISCLAIMED. IN NO EVENT SHALL THE COPYRIGHT HOLDER OR CONTRIBUTORS BE LIABLE
  * FOR ANY DIRECT, INDIRECT, INCIDENTAL, SPECIAL, EXEMPLARY, OR CONSEQUENTIAL
  * DAMAGES (INCLUDING, BUT NOT LIMITED TO, PROCUREMENT OF SUBSTITUTE GOODS OR
  * SERVICES; LOSS OF USE, DATA, OR PROFITS; OR BUSINESS INTERRUPTION) HOWEVER
  * CAUSED AND ON ANY THEORY OF LIABILITY, WHETHER IN CONTRACT, STRICT LIABILITY,
  * OR TORT (INCLUDING NEGLIGENCE OR OTHERWISE) ARISING IN ANY WAY OUT OF THE USE
  * OF THIS SOFTWARE, EVEN IF ADVISED OF THE POSSIBILITY OF SUCH DAMAGE.
  *
  ******************************************************************************
  */

#include "stm32f4xx_hal.h"
#include "adc.h"
#include "dma.h"
#include "i2c.h"
#include "spi.h"
#include "tim.h"
#include "usart.h"
#include "usb_otg.h"
#include "gpio.h"

/* USER CODE BEGIN 0 */
void app_preinit(void);
void app_postinit(void);
void app_main(void);
/* USER CODE END 0 */

void SystemClock_Config(void);

int main(void)
{

  /* USER CODE BEGIN 1 */
	app_preinit();
  /* USER CODE END 1 */

  /* MCU Configuration----------------------------------------------------------*/

  /* Reset of all peripherals, Initializes the Flash interface and the Systick. */
  HAL_Init();

  /* Configure the system clock */
  SystemClock_Config();

  /* System interrupt init*/
  /* Sets the priority grouping field */
  HAL_NVIC_SetPriorityGrouping(NVIC_PRIORITYGROUP_4);
  HAL_NVIC_SetPriority(SysTick_IRQn, 0, 0);

  /* Initialize all configured peripherals */
  MX_GPIO_Init();
  MX_DMA_Init();
  MX_ADC1_Init();
  MX_I2C2_Init();
  MX_I2C3_Init();
  MX_SPI1_Init();
  MX_SPI2_Init();
  MX_SPI3_Init();
  MX_SPI4_Init();
  MX_SPI5_Init();
  MX_SPI6_Init();
  MX_TIM1_Init();
  MX_TIM3_Init();
  MX_TIM4_Init();
  MX_TIM5_Init();
  MX_TIM6_Init();
  MX_TIM8_Init();
  MX_USART3_Init();
  MX_USB_OTG_FS_USB_Init();

  /* USER CODE BEGIN 2 */
	app_postinit();
  /* USER CODE END 2 */

  /* USER CODE BEGIN 3 */
	/* Infinite loop */
	while (1)
	{
		app_main();
	}
  /* USER CODE END 3 */

}

/** System Clock Configuration
*/
void SystemClock_Config(void)
{

  RCC_ClkInitTypeDef RCC_ClkInitStruct;
  RCC_OscInitTypeDef RCC_OscInitStruct;

  __PWR_CLK_ENABLE();

  __HAL_PWR_VOLTAGESCALING_CONFIG(PWR_REGULATOR_VOLTAGE_SCALE1);

  RCC_OscInitStruct.OscillatorType = RCC_OSCILLATORTYPE_HSI;
  RCC_OscInitStruct.HSIState = RCC_HSI_ON;
  RCC_OscInitStruct.HSICalibrationValue = 6;
  RCC_OscInitStruct.PLL.PLLState = RCC_PLL_ON;
  RCC_OscInitStruct.PLL.PLLSource = RCC_PLLSOURCE_HSI;
  RCC_OscInitStruct.PLL.PLLM = 16;
  RCC_OscInitStruct.PLL.PLLN = 336;
  RCC_OscInitStruct.PLL.PLLP = RCC_PLLP_DIV2;
  RCC_OscInitStruct.PLL.PLLQ = 7;
  HAL_RCC_OscConfig(&RCC_OscInitStruct);

  RCC_ClkInitStruct.ClockType = RCC_CLOCKTYPE_SYSCLK|RCC_CLOCKTYPE_PCLK1
                              |RCC_CLOCKTYPE_PCLK2;
  RCC_ClkInitStruct.SYSCLKSource = RCC_SYSCLKSOURCE_PLLCLK;
  RCC_ClkInitStruct.AHBCLKDivider = RCC_SYSCLK_DIV1;
  RCC_ClkInitStruct.APB1CLKDivider = RCC_HCLK_DIV4;
  RCC_ClkInitStruct.APB2CLKDivider = RCC_HCLK_DIV2;
  HAL_RCC_ClockConfig(&RCC_ClkInitStruct, FLASH_LATENCY_5);

}

/* USER CODE BEGIN 4 */
__weak void app_preinit(void)
{

}

__weak void app_postinit(void)
{

}

__weak void app_main(void)
{

}
/* USER CODE END 4 */

/************************ (C) COPYRIGHT STMicroelectronics *****END OF FILE****/
